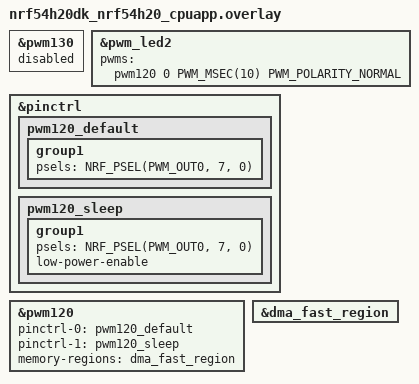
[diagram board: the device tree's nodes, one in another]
/*
 * Copyright (c) 2024 Nordic Semiconductor ASA
 * SPDX-License-Identifier: Apache-2.0
 *
 * Test requires wire connection between:
 *  - PWM120 OUT[0] at P7.0
 *  - LED[0-4] input at P9.[0-4]
 */

#include <zephyr/dt-bindings/pwm/pwm.h>
#include <zephyr/dt-bindings/gpio/gpio.h>
#include <zephyr/dt-bindings/gpio/nordic-nrf-gpio.h>

&pwm130 {
	status = "disabled";
};

&pwm_led2 {
	// pwms = <&pwm130 0 PWM_MSEC(10) PWM_POLARITY_NORMAL>;
	pwms = <&pwm120 0 PWM_MSEC(10) PWM_POLARITY_NORMAL>;
};

&pinctrl {
	pwm120_default: pwm120_default {
		group1 {
			psels = <NRF_PSEL(PWM_OUT0, 7, 0)>;
		};
	};
	pwm120_sleep: pwm120_sleep {
		group1 {
			psels = <NRF_PSEL(PWM_OUT0, 7, 0)>;
			low-power-enable;
		};
	};
};

&pwm120 {
	status = "okay";
	pinctrl-0 = <&pwm120_default>;
	pinctrl-1 = <&pwm120_sleep>;
	pinctrl-names = "default", "sleep";
	memory-regions = <&dma_fast_region>;
};

&dma_fast_region {
	status = "okay";
};
